VERSION "1.0"
BS_:
BU_: Vehicle Cockpit

BO_ 385 ENGINE: 8 Vehicle
 SG_ ENGINE_RPM : 7|16@0+ (0.125,0) [0|6000] "RPM" Cockpit
 SG_ VEHICLE_SPEED : 63|8@0+ (1,0) [0|255] "km/h" Cockpit

BO_ 533 GEARBOX: 6 Vehicle
 SG_ REVERSE_GEAR : 14|1@0+ (1,0) [0|1] "" Cockpit

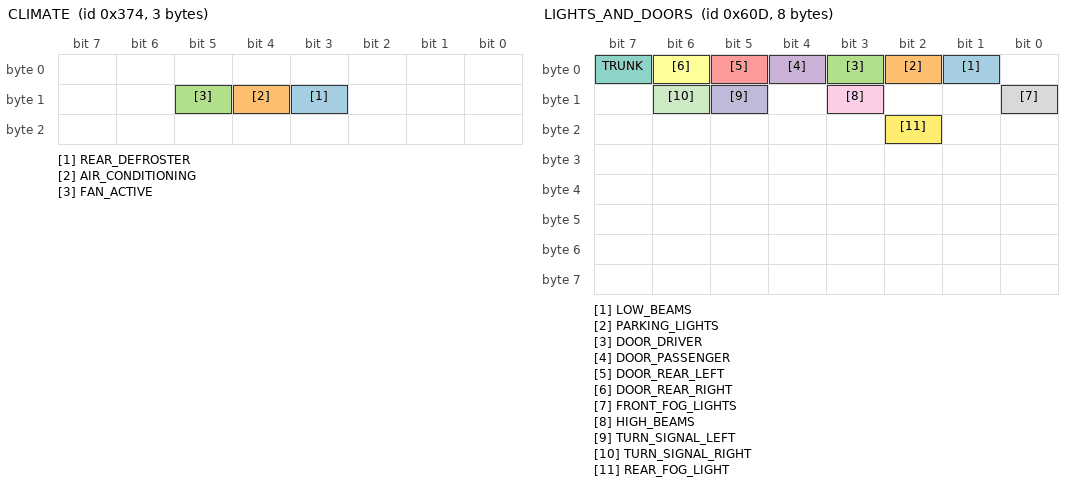
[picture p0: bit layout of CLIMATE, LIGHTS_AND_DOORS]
BO_ 884 CLIMATE: 3 Vehicle
 SG_ REAR_DEFROSTER : 11|1@0+ (1,0) [0|1] "" Cockpit
 SG_ AIR_CONDITIONING : 12|1@0+ (1,0) [0|1] "" Cockpit
 SG_ FAN_ACTIVE : 13|1@0+ (1,0) [0|1] "" Cockpit

BO_ 1477 BRAKES: 8 Vehicle
 SG_ PARKING_BRAKE : 2|1@0+ (1,0) [0|1] "" Cockpit

BO_ 1549 LIGHTS_AND_DOORS: 8 Vehicle
 SG_ LOW_BEAMS : 1|1@0+ (1,0) [0|1] "" Cockpit
 SG_ PARKING_LIGHTS : 2|1@0+ (1,0) [0|1] "" Cockpit
 SG_ DOOR_DRIVER : 3|1@0+ (1,0) [0|1] "" Cockpit
 SG_ DOOR_PASSENGER : 4|1@0+ (1,0) [0|1] "" Cockpit
 SG_ DOOR_REAR_LEFT : 5|1@0+ (1,0) [0|1] "" Cockpit
 SG_ DOOR_REAR_RIGHT : 6|1@0+ (1,0) [0|1] "" Cockpit
 SG_ TRUNK : 7|1@0+ (1,0) [0|1] "" Cockpit
 SG_ FRONT_FOG_LIGHTS : 8|1@0+ (1,0) [0|1] "" Cockpit
 SG_ HIGH_BEAMS : 11|1@0+ (1,0) [0|1] "" Cockpit
 SG_ TURN_SIGNAL_LEFT : 13|1@0+ (1,0) [0|1] "" Cockpit
 SG_ TURN_SIGNAL_RIGHT : 14|1@0+ (1,0) [0|1] "" Cockpit
 SG_ REAR_FOG_LIGHT : 18|1@0+ (1,0) [0|1] "" Cockpit

BO_ 1617 SAFETY: 2 Vehicle
 SG_ SEATBELT_UNFASTENED : 8|1@0+ (1,0) [0|1] "" Cockpit
